# MWPR1516 register map
Vendor: Freescale Semiconductor, Inc.; Series: Kinetis; File version: 1.6
MWPR1516 Freescale Microcontroller
CPU: CM0PLUS r0p0, little endian, no MPU, no FPU, VTOR, 2 interrupt priority bits
Registers are 8-bit, read-write, reset 0x0 unless marked. A register's access mark holds for its fields unless they carry their own. Offsets are from the block's base; lines under a group give offsets from that group; [hi:lo] are bit positions; {n}, {i} and the like mark numbered series; 'fields as' and 'values as' point back to an identical list; <NAME> marks a mode.

## Memory map
0x00000400 FTMRE_FlashConfig size 0x10 — Flash configuration field
0x4000F000 GPIOA size 0x1C — General Purpose Input/Output
0x40020000 FTMRE blocks up to offset 0x10 — Flash Memory
0x40031000 IRQ size 0x1 — Interrupt
0x40034000 FSKDT size 0x14 — FSK Demodulation Timer
0x40037000 PIT size 0x120 — Periodic Interrupt Timer
0x40038000 FTM0 size 0x70 — FlexTimer Module
0x4003A000 FTM1 size 0x70 — FlexTimer Module
0x4003B000 ADC size 0x28 — Analog-to-Digital Converter
0x4003D000 RTC size 0xC — Real-time counter
0x40048000 SIM size 0x4C — System Integration Module
0x40049000 PORT size 0x8 — Port control and interrupts
0x40052000 WDOG size 0x8 — Watchdog timer
0x40064000 ICS size 0x5 — Clock management
0x40065000 OSC size 0x1 — Oscillator
0x40066000 I2C0 size 0xC — Inter-Integrated Circuit
0x4006A000 UART0 size 0x8 — Universal Asynchronous Receiver/Transmitter (UART)
0x4006E000 CNC size 0xE — Communication and Clamp Controller
0x40070000 LDO size 0xE — Low Dropout Regulator
0x40071000 PGA size 0x1 — Programmable Gain Amplifier
0x40073000 ACMP0 size 0x4 — Analog comparator
0x4007D000 PMC size 0xA — Power Management Controller
0xF0003000 MCM blocks up to offset 0x10 — Core Platform Miscellaneous Control Module

## Interrupts
5 FTMRE
6 PMC
7 IRQ
8 I2C0
12 UART0
14 ADC_ERR_ABORT (ADC)
15 ADC_CONV_COMPLETE (ADC)
16 ACMP0
17 FTM0
18 FTM1
20 RTC
22 PIT_CH0 (PIT)
23 PIT_CH1 (PIT)
26 FSKDT
27 ICS
28 WDOG
30 CNC
31 LDO

## FTMRE_FlashConfig — Flash configuration field
Base 0x00000400; register names take the prefix NV_
{0x0+i} BACKKEY{i} ro reset 0xFF (i=0..7) — Backdoor Comparison Key {i}
  [7:0] KEY — Backdoor Comparison Key.
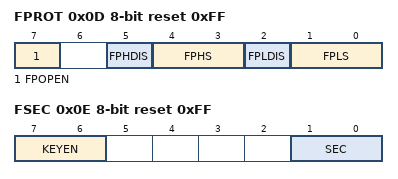
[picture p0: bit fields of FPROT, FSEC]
0x0D FPROT ro reset 0xFF — Non-volatile P-Flash Protection Register
  [7] FPOPEN
    0=FPHDIS and FPLDIS bits define unprotected address ranges as specified by the corresponding FPHS and FPLS bits FPROT1.1; 1=FPHDIS and FPLDIS bits enable protection for the address range specified by the corresponding FPHS and FPLS bits
  [5] FPHDIS
    0=Protection/Unprotection enabled; 1=Protection/Unprotection disabled
  [4:3] FPHS
    0=Address range: 0x00_7C00-0x00_7FFF; protected size: 1 KB; 1=Address range: 0x00_7800-0x00_7FFF; protected size: 2 KB; 2=Address range: 0x00_7000-0x00_7FFF; protected size: 4 KB; 3=Address range: 0x00_6000-0x00_7FFF; protected size: 8 KB
  [2] FPLDIS
    values as FPHDIS
  [1:0] FPLS
    0=Address range: 0x00_0000-0x00_07FF; protected size: 2 KB; 1=Address range: 0x00_0000-0x00_0FFF; protected size: 4 KB; 2=Address range: 0x00_0000-0x00_1FFF; protected size: 8 KB; 3=Address range: 0x00_0000-0x00_3FFF; protected size: 16 KB
0x0E FSEC ro reset 0xFF — Non-volatile Flash Security Register
  [7:6] KEYEN — Backdoor Key Security Enable
    2=Backdoor key access enabled; 3=Backdoor key access disabled
  [1:0] SEC — Flash Security
    2=MCU security status is unsecure; 3=MCU security status is secure
0x0F FOPT ro reset 0xFF — Non-volatile Flash Option Register

## Licence text in the file
Redistribution and use in source and binary forms, with or without modification, are permitted provided that the following conditions are met: o Redistributions of source code must retain the above copyright notice, this list of conditions and the following disclaimer. o Redistributions in binary form must reproduce the above copyright notice, this list of conditions and the following disclaimer in the documentation and/or other materials provided with the distribution. o Neither the name of Freescale Semiconductor, Inc. nor the names of its contributors may be used to endorse or promote products derived from this software without specific prior written permission. THIS SOFTWARE IS PROVIDED BY THE COPYRIGHT HOLDERS AND CONTRIBUTORS "AS IS" AND. ANY EXPRESS OR IMPLIED WARRANTIES, INCLUDING, BUT NOT LIMITED TO, THE IMPLIED. WARRANTIES OF MERCHANTABILITY AND FITNESS FOR A PARTICULAR PURPOSE ARE. DISCLAIMED. IN NO EVENT SHALL THE COPYRIGHT HOLDER OR CONTRIBUTORS BE LIABLE FOR. ANY DIRECT, INDIRECT, INCIDENTAL, SPECIAL, EXEMPLARY, OR CONSEQUENTIAL DAMAGES (INCLUDING, BUT NOT LIMITED TO, PROCUREMENT OF SUBSTITUTE GOODS OR SERVICES; LOSS OF USE, DATA, OR PROFITS; OR BUSINESS INTERRUPTION) HOWEVER CAUSED AND ON. ANY THEORY OF LIABILITY, WHETHER IN CONTRACT, STRICT LIABILITY, OR TORT (INCLUDING NEGLIGENCE OR OTHERWISE) ARISING IN ANY WAY OUT OF THE USE OF THIS. SOFTWARE, EVEN IF ADVISED OF THE POSSIBILITY OF SUCH DAMAGE.
